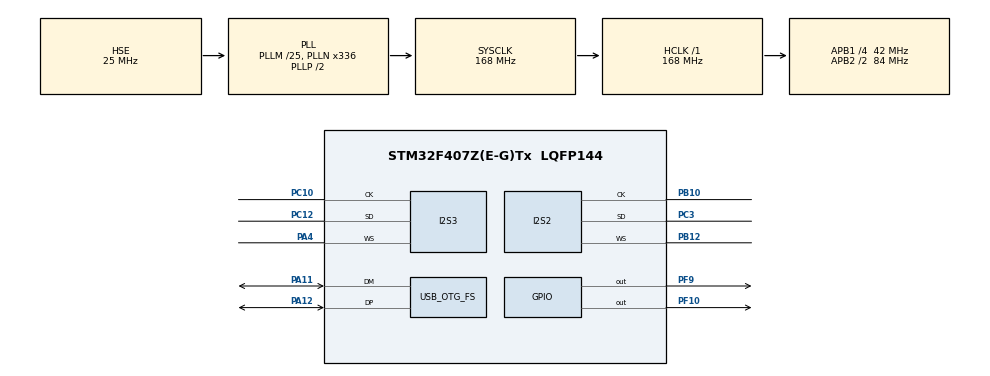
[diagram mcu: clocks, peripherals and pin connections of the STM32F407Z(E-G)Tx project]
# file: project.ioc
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Dma.Request0=SPI2_TX
Dma.Request1=SPI3_TX
Dma.SPI2_TX.0.Direction=DMA_MEMORY_TO_PERIPH
Dma.SPI2_TX.0.FIFOMode=DMA_FIFOMODE_DISABLE
Dma.SPI2_TX.0.Instance=DMA1_Stream4
Dma.SPI2_TX.0.MemDataAlignment=DMA_MDATAALIGN_WORD
Dma.SPI2_TX.0.MemInc=DMA_MINC_ENABLE
Dma.SPI2_TX.0.Mode=DMA_CIRCULAR
Dma.SPI2_TX.0.PeriphDataAlignment=DMA_PDATAALIGN_WORD
Dma.SPI2_TX.0.PeriphInc=DMA_PINC_DISABLE
Dma.SPI2_TX.0.Priority=DMA_PRIORITY_LOW
Dma.SPI3_TX.1.Direction=DMA_MEMORY_TO_PERIPH
Dma.SPI3_TX.1.FIFOMode=DMA_FIFOMODE_DISABLE
Dma.SPI3_TX.1.Instance=DMA1_Stream5
Dma.SPI3_TX.1.MemDataAlignment=DMA_MDATAALIGN_WORD
Dma.SPI3_TX.1.MemInc=DMA_MINC_ENABLE
Dma.SPI3_TX.1.Mode=DMA_CIRCULAR
Dma.SPI3_TX.1.PeriphDataAlignment=DMA_PDATAALIGN_WORD
Dma.SPI3_TX.1.PeriphInc=DMA_PINC_DISABLE
Dma.SPI3_TX.1.Priority=DMA_PRIORITY_LOW
I2S2.AudioFreq=I2S_AUDIOFREQ_48K
I2S2.DataFormat=I2S_DATAFORMAT_24B
I2S2.ErrorAudioFreq=0.75 %
I2S2.FullDuplexMode=I2S_FULLDUPLEXMODE_DISABLE
I2S2.Instance=SPI$Index
I2S2.RealAudioFreq=48.363 KHz
I2S2.VirtualMode=I2S_MODE_MASTER
I2S3.AudioFreq=I2S_AUDIOFREQ_48K
I2S3.DataFormat=I2S_DATAFORMAT_24B
I2S3.ErrorAudioFreq=0.75 %
I2S3.FullDuplexMode=I2S_FULLDUPLEXMODE_DISABLE
I2S3.Instance=SPI$Index
I2S3.RealAudioFreq=48.363 KHz
I2S3.VirtualMode=I2S_MODE_MASTER
Mcu.Family=STM32F4
Mcu.Name=STM32F407Z(E-G)Tx
Mcu.Package=LQFP144
NVIC.DMA1_Stream4_IRQn=true\:0\:0\:false\:false\:true\:false\:true\:true
NVIC.DMA1_Stream5_IRQn=true\:0\:0\:false\:false\:true\:false\:true\:true
NVIC.OTG_FS_IRQn=true\:0\:0\:false\:false\:true\:false\:true\:true
NVIC.PriorityGroup=NVIC_PRIORITYGROUP_4
PA11.Mode=Device_Only
PA11.Signal=USB_OTG_FS_DM
PA12.GPIO_PuPd=GPIO_PULLUP
PA12.Mode=Device_Only
PA12.Signal=USB_OTG_FS_DP
PA13.Mode=Serial_Wire
PA13.Signal=SYS_JTMS-SWDIO
PA14.Mode=Serial_Wire
PA14.Signal=SYS_JTCK-SWCLK
PA4.Mode=Half_Duplex_Master
PA4.Signal=I2S3_WS
PB10.Mode=Half_Duplex_Master
PB10.Signal=I2S2_CK
PB12.Mode=Half_Duplex_Master
PB12.Signal=I2S2_WS
PC10.Mode=Half_Duplex_Master
PC10.Signal=I2S3_CK
PC12.Mode=Half_Duplex_Master
PC12.Signal=I2S3_SD
PC3.Mode=Half_Duplex_Master
PC3.Signal=I2S2_SD
PF10.Signal=GPIO_Output
PF9.Signal=GPIO_Output
PH0-OSC_IN.Mode=HSE-External-Oscillator
PH0-OSC_IN.Signal=RCC_OSC_IN
PH1-OSC_OUT.Mode=HSE-External-Oscillator
PH1-OSC_OUT.Signal=RCC_OSC_OUT
ProjectManager.HeapSize=0x500
ProjectManager.StackSize=0x500
ProjectManager.TargetToolchain=STM32CubeIDE
RCC.48MHZClocksFreq_Value=48000000
RCC.AHBFreq_Value=168000000
RCC.APB1CLKDivider=RCC_HCLK_DIV4
RCC.APB1Freq_Value=42000000
RCC.APB1TimFreq_Value=84000000
RCC.APB2CLKDivider=RCC_HCLK_DIV2
RCC.APB2Freq_Value=84000000
RCC.APB2TimFreq_Value=168000000
RCC.CortexFreq_Value=168000000
RCC.HCLKFreq_Value=168000000
RCC.HSE_VALUE=25000000
RCC.HSI_VALUE=16000000
RCC.LSE_VALUE=32768
RCC.PLLI2SN=260
RCC.PLLM=25
RCC.PLLN=336
RCC.PLLQ=7
RCC.SYSCLKFreq_VALUE=168000000
RCC.SYSCLKSource=RCC_SYSCLKSOURCE_PLLCLK
RCC.VCOOutputFreq_Value=336000000
USB_DEVICE.CLASS_NAME_FS=CDC
USB_DEVICE.VirtualMode-CDC_FS=Cdc
USB_DEVICE.VirtualModeFS=Cdc_FS
USB_OTG_FS.VirtualMode=Device_Only
VP_USB_DEVICE_VS_USB_DEVICE_CDC_FS.Mode=CDC_FS
board=custom

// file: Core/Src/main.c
/* USER CODE BEGIN Header */
/**
  ******************************************************************************
  * @file           : main.c
  * @brief          : Main program body
  ******************************************************************************
  * @attention
  *
  * Copyright (c) 2024 STMicroelectronics.
  * All rights reserved.
  *
  * This software is licensed under terms that can be found in the LICENSE file
  * in the root directory of this software component.
  * If no LICENSE file comes with this software, it is provided AS-IS.
  *
  ******************************************************************************
  */
/* USER CODE END Header */
#include "main.h"
#include "dma.h"
#include "i2s.h"
#include "usb_device.h"
#include "gpio.h"

/* USER CODE BEGIN Includes */
#include "usb_user.h"
/* USER CODE END Includes */

/* USER CODE BEGIN PV */
extern uint8_t Rx_status;
/* USER CODE END PV */

void SystemClock_Config(void);
void PeriphCommonClock_Config(void);

int main(void)
{

  /* USER CODE BEGIN 1 */
  uint8_t Rx_buffer[32];
  /* USER CODE END 1 */

  /* MCU Configuration--------------------------------------------------------*/

  /* Reset of all peripherals, Initializes the Flash interface and the Systick. */
  HAL_Init();

  /* Configure the system clock */
  SystemClock_Config();

  /* Configure the peripherals common clocks */
  PeriphCommonClock_Config();

  /* Initialize all configured peripherals */
  MX_GPIO_Init();
  MX_DMA_Init();
  MX_I2S2_Init();
  MX_I2S3_Init();
  MX_USB_DEVICE_Init();
  /* USER CODE BEGIN 2 */
  usb_vbc_Receive_It(Rx_buffer,16);
  /* USER CODE END 2 */

  /* Infinite loop */
  while (1)
  {

    /* USER CODE BEGIN 3 */
    HAL_GPIO_TogglePin(GPIOF,GPIO_PIN_10);

    if(Rx_status==1)
    {
        usb_printf("这里是小周");
        usb_vbc_Receive_It(Rx_buffer,16);
    }

    HAL_Delay(100);
  }
  /* USER CODE END 3 */
}

void SystemClock_Config(void)
{
  RCC_OscInitTypeDef RCC_OscInitStruct = {0};
  RCC_ClkInitTypeDef RCC_ClkInitStruct = {0};

  /** Configure the main internal regulator output voltage
  */
  __HAL_RCC_PWR_CLK_ENABLE();
  __HAL_PWR_VOLTAGESCALING_CONFIG(PWR_REGULATOR_VOLTAGE_SCALE1);

  /** Initializes the RCC Oscillators according to the specified parameters
  * in the RCC_OscInitTypeDef structure.
  */
  RCC_OscInitStruct.OscillatorType = RCC_OSCILLATORTYPE_HSE;
  RCC_OscInitStruct.HSEState = RCC_HSE_ON;
  RCC_OscInitStruct.PLL.PLLState = RCC_PLL_ON;
  RCC_OscInitStruct.PLL.PLLSource = RCC_PLLSOURCE_HSE;
  RCC_OscInitStruct.PLL.PLLM = 25;
  RCC_OscInitStruct.PLL.PLLN = 336;
  RCC_OscInitStruct.PLL.PLLP = RCC_PLLP_DIV2;
  RCC_OscInitStruct.PLL.PLLQ = 7;
  if (HAL_RCC_OscConfig(&RCC_OscInitStruct) != HAL_OK)
  {
    Error_Handler();
  }

  /** Initializes the CPU, AHB and APB buses clocks
  */
  RCC_ClkInitStruct.ClockType = RCC_CLOCKTYPE_HCLK|RCC_CLOCKTYPE_SYSCLK
                              |RCC_CLOCKTYPE_PCLK1|RCC_CLOCKTYPE_PCLK2;
  RCC_ClkInitStruct.SYSCLKSource = RCC_SYSCLKSOURCE_PLLCLK;
  RCC_ClkInitStruct.AHBCLKDivider = RCC_SYSCLK_DIV1;
  RCC_ClkInitStruct.APB1CLKDivider = RCC_HCLK_DIV4;
  RCC_ClkInitStruct.APB2CLKDivider = RCC_HCLK_DIV2;

  if (HAL_RCC_ClockConfig(&RCC_ClkInitStruct, FLASH_LATENCY_5) != HAL_OK)
  {
    Error_Handler();
  }
}

void PeriphCommonClock_Config(void)
{
  RCC_PeriphCLKInitTypeDef PeriphClkInitStruct = {0};

  /** Initializes the peripherals clock
  */
  PeriphClkInitStruct.PeriphClockSelection = RCC_PERIPHCLK_I2S;
  PeriphClkInitStruct.PLLI2S.PLLI2SN = 260;
  PeriphClkInitStruct.PLLI2S.PLLI2SR = 2;
  if (HAL_RCCEx_PeriphCLKConfig(&PeriphClkInitStruct) != HAL_OK)
  {
    Error_Handler();
  }
}

void Error_Handler(void)
{
  __disable_irq();
  while (1)
  {
  }
}
